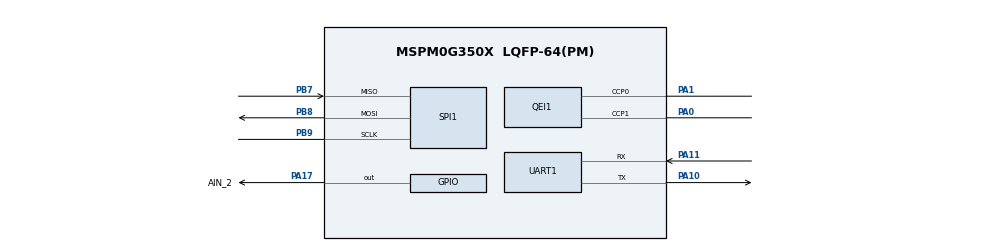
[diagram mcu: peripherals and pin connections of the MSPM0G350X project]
/**
 * @cliArgs --device "MSPM0G350X" --part "Default" --package "LQFP-64(PM)" --product "mspm0_sdk@2.10.00.04"
 * @versions {"tool":"1.26.2+4477"}
 */

/**
 * Import the modules used in this configuration.
 */
const ADC12  = scripting.addModule("/ti/driverlib/ADC12", {}, false);
const ADC121 = ADC12.addInstance();
const GPIO   = scripting.addModule("/ti/driverlib/GPIO", {}, false);
const GPIO1  = GPIO.addInstance();
const GPIO2  = GPIO.addInstance();
const GPIO3  = GPIO.addInstance();
const PWM    = scripting.addModule("/ti/driverlib/PWM", {}, false);
const PWM1   = PWM.addInstance();
const QEI    = scripting.addModule("/ti/driverlib/QEI", {}, false);
const QEI1   = QEI.addInstance();
const SPI    = scripting.addModule("/ti/driverlib/SPI", {}, false);
const SPI1   = SPI.addInstance();
const SYSCTL = scripting.addModule("/ti/driverlib/SYSCTL");
const TIMER  = scripting.addModule("/ti/driverlib/TIMER", {}, false);
const TIMER1 = TIMER.addInstance();
const UART   = scripting.addModule("/ti/driverlib/UART", {}, false);
const UART1  = UART.addInstance();

/**
 * Write custom configuration values to the imported modules.
 */
ADC121.$name                             = "ADC_voltage";
ADC121.enabledInterrupts                 = ["DL_ADC12_INTERRUPT_MEM0_RESULT_LOADED"];
ADC121.powerDownMode                     = "DL_ADC12_POWER_DOWN_MODE_MANUAL";
ADC121.sampleTime0                       = "125us";
ADC121.adcPin0Config.$name               = "ti_driverlib_gpio_GPIOPinGeneric0";
ADC121.adcPin0Config.hideOutputInversion = scripting.forceWrite(false);

const Board = scripting.addModule("/ti/driverlib/Board", {}, false);

GPIO1.$name                         = "LCD";
GPIO1.port                          = "PORTB";
GPIO1.associatedPins.create(4);
GPIO1.associatedPins[0].ioStructure = "SD";
GPIO1.associatedPins[0].assignedPin = "10";
GPIO1.associatedPins[0].$name       = "RES";
GPIO1.associatedPins[1].$name       = "DC";
GPIO1.associatedPins[1].ioStructure = "SD";
GPIO1.associatedPins[1].assignedPin = "11";
GPIO1.associatedPins[2].$name       = "CS";
GPIO1.associatedPins[2].ioStructure = "SD";
GPIO1.associatedPins[2].assignedPin = "14";
GPIO1.associatedPins[3].$name       = "BLK";
GPIO1.associatedPins[3].assignedPin = "26";

GPIO2.$name                         = "MOTOR";
GPIO2.port                          = "PORTA";
GPIO2.associatedPins.create(2);
GPIO2.associatedPins[0].$name       = "AIN_1";
GPIO2.associatedPins[0].ioStructure = "SD";
GPIO2.associatedPins[0].assignedPin = "16";
GPIO2.associatedPins[1].$name       = "AIN_2";
GPIO2.associatedPins[1].pin.$assign = "PA17";

GPIO3.$name                                 = "MOTOR_STOP";
GPIO3.port                                  = "PORTB";
GPIO3.associatedPins[0].$name               = "STOP";
GPIO3.associatedPins[0].direction           = "INPUT";
GPIO3.associatedPins[0].ioStructure         = "SD";
GPIO3.associatedPins[0].assignedPortSegment = "Upper";
GPIO3.associatedPins[0].assignedPin         = "21";
GPIO3.associatedPins[0].interruptEn         = true;
GPIO3.associatedPins[0].polarity            = "FALL";

PWM1.$name                              = "PWM_MOTOR";
PWM1.clockDivider                       = 4;
PWM1.pwmMode                            = "EDGE_ALIGN_UP";
PWM1.ccIndex                            = [0];
PWM1.PWM_CHANNEL_0.$name                = "ti_driverlib_pwm_PWMTimerCC0";
PWM1.ccp0PinConfig.direction            = scripting.forceWrite("OUTPUT");
PWM1.ccp0PinConfig.hideOutputInversion  = scripting.forceWrite(false);
PWM1.ccp0PinConfig.onlyInternalResistor = scripting.forceWrite(false);
PWM1.ccp0PinConfig.passedPeripheralType = scripting.forceWrite("Digital");
PWM1.ccp0PinConfig.$name                = "ti_driverlib_gpio_GPIOPinGeneric6";
PWM1.peripheral.$assign                 = "TIMG0";

QEI1.$name                      = "QEI_0";
QEI1.interrupts                 = ["DC_EVENT"];
QEI1.peripheral.ccp0Pin.$assign = "PA1";
QEI1.peripheral.ccp1Pin.$assign = "PA0";
QEI1.ccp0PinConfig.$name        = "ti_driverlib_gpio_GPIOPinGeneric7";
QEI1.ccp1PinConfig.$name        = "ti_driverlib_gpio_GPIOPinGeneric8";

SPI1.$name                              = "SPI_LCD";
SPI1.frameFormat                        = "MOTO3";
SPI1.sclkPinConfig.direction            = scripting.forceWrite("OUTPUT");
SPI1.sclkPinConfig.onlyInternalResistor = scripting.forceWrite(false);
SPI1.sclkPinConfig.passedPeripheralType = scripting.forceWrite("Digital");
SPI1.sclkPinConfig.$name                = "ti_driverlib_gpio_GPIOPinGeneric1";
SPI1.mosiPinConfig.direction            = scripting.forceWrite("OUTPUT");
SPI1.mosiPinConfig.hideOutputInversion  = scripting.forceWrite(false);
SPI1.mosiPinConfig.onlyInternalResistor = scripting.forceWrite(false);
SPI1.mosiPinConfig.passedPeripheralType = scripting.forceWrite("Digital");
SPI1.mosiPinConfig.$name                = "ti_driverlib_gpio_GPIOPinGeneric2";
SPI1.misoPinConfig.onlyInternalResistor = scripting.forceWrite(false);
SPI1.misoPinConfig.passedPeripheralType = scripting.forceWrite("Digital");
SPI1.misoPinConfig.$name                = "ti_driverlib_gpio_GPIOPinGeneric3";
SPI1.peripheral.$assign                 = "SPI1";
SPI1.peripheral.sclkPin.$assign         = "PB9";
SPI1.peripheral.mosiPin.$assign         = "PB8";
SPI1.peripheral.misoPin.$assign         = "PB7";

SYSCTL.forceDefaultClkConfig = true;

TIMER1.$name              = "TIMER_0";
TIMER1.timerClkDiv        = 8;
TIMER1.timerMode          = "PERIODIC_UP";
TIMER1.timerStartTimer    = true;
TIMER1.interrupts         = ["LOAD"];
TIMER1.timerClkPrescale   = 256;
TIMER1.timerPeriod        = "1s";
TIMER1.peripheral.$assign = "TIMA0";

UART1.$name                    = "UART_0";
UART1.targetBaudRate           = 115200;
UART1.peripheral.rxPin.$assign = "PA11";
UART1.peripheral.txPin.$assign = "PA10";
UART1.txPinConfig.$name        = "ti_driverlib_gpio_GPIOPinGeneric4";
UART1.rxPinConfig.$name        = "ti_driverlib_gpio_GPIOPinGeneric5";

/**
 * Pinmux solution for unlocked pins/peripherals. This ensures that minor changes to the automatic solver in a future
 * version of the tool will not impact the pinmux you originally saw.  These lines can be completely deleted in order to
 * re-solve from scratch.
 */
ADC121.peripheral.$suggestSolution           = "ADC1";
ADC121.peripheral.adcPin0.$suggestSolution   = "PA15";
Board.peripheral.$suggestSolution            = "DEBUGSS";
Board.peripheral.swclkPin.$suggestSolution   = "PA20";
Board.peripheral.swdioPin.$suggestSolution   = "PA19";
GPIO1.associatedPins[0].pin.$suggestSolution = "PB10";
GPIO1.associatedPins[1].pin.$suggestSolution = "PB11";
GPIO1.associatedPins[2].pin.$suggestSolution = "PB14";
GPIO1.associatedPins[3].pin.$suggestSolution = "PB26";
GPIO2.associatedPins[0].pin.$suggestSolution = "PA16";
GPIO3.associatedPins[0].pin.$suggestSolution = "PB21";
PWM1.peripheral.ccp0Pin.$suggestSolution     = "PA12";
QEI1.peripheral.$suggestSolution             = "TIMG8";
SYSCTL.peripheral.$suggestSolution           = "SYSCTL";
UART1.peripheral.$suggestSolution            = "UART0";
